# TIMEOUT_KSBUS_VBUSM_TO_GASKET_04301000h register map
Vendor: Texas Instruments
Peripheral module from a debugger description file (folder am62D).
Registers are 32-bit, read-only, reset 0x0 unless marked. A register's access mark holds for its fields unless they carry their own. Offsets are as the file gives them; lines under a group give offsets from that group; [hi:lo] are bit positions; {n}, {i} and the like mark numbered series; 'fields as' and 'values as' point back to an identical list; <NAME> marks a mode.

## ksbus_vbusm_to_gasket
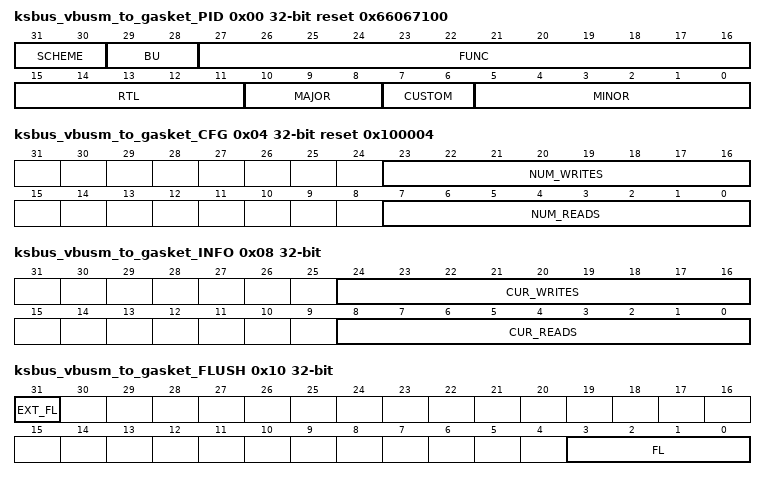
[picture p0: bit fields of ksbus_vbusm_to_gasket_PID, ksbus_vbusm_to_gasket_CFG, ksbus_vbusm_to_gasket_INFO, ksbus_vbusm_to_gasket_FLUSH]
0x00 ksbus_vbusm_to_gasket_PID reset 0x66067100 — The Revision Register contains the major and minor revisions for the module.
  [31:30] SCHEME — PID register scheme Reset Source: rst_mod_g_rst_n
  [29:28] BU — Business Unit: 10 = Processors Reset Source: rst_mod_g_rst_n
  [27:16] FUNC — Module ID Reset Source: rst_mod_g_rst_n
  [15:11] RTL — RTL revision. Will vary depending on release. Reset Source: rst_mod_g_rst_n
  [10:8] MAJOR — Major revision Reset Source: rst_mod_g_rst_n
  [7:6] CUSTOM — Custom Reset Source: rst_mod_g_rst_n
  [5:0] MINOR — Minor revision Reset Source: rst_mod_g_rst_n
0x04 ksbus_vbusm_to_gasket_CFG reset 0x100004 — The Configuration Register contains information about the configuration of the gasket.
  [23:16] NUM_WRITES — Total Number of slots in the write scoreboard Reset Source: rst_mod_g_rst_n
  [7:0] NUM_READS — Total Number of slots in the read scoreboard Reset Source: rst_mod_g_rst_n
0x08 ksbus_vbusm_to_gasket_INFO — The Info Register contains information about the current state of the gasket.
  [24:16] CUR_WRITES — Current number of occupied slots in the write scoreboard Reset Source: rst_mod_g_rst_n
  [8:0] CUR_READS — Current number of occupied slots in the read scoreboard Reset Source: rst_mod_g_rst_n
0x0C ksbus_vbusm_to_gasket_ENABLE rw — The Enable Register contains the gasket enable.
  [3:0] EN — Enable. 0 - Disabled, All other values - Enabled. Reset Source: rst_mod_g_rst_n
0x10 ksbus_vbusm_to_gasket_FLUSH access per field — The Flush Register contains software flush control.
  [31] EXT_FL ro — The value of external flush input Reset Source: rst_mod_g_rst_n
  [3:0] FL rw — SW control and indicator for whether the gasket is in flush mode. 4'b1111 - Flush mode, All other values - Normal mode. Reset Source: rst_mod_g_rst_n
0x14 ksbus_vbusm_to_gasket_TIMEOUT rw reset 0x3FFFFFFF — The Timeout Value Register contains the timeout value for scoreboarded transactions.
  [29:0] TO — The number of cycles in each eon. Each transaction can be outstanding for 2-3 eons before it times out. Reset Source: rst_mod_g_rst_n
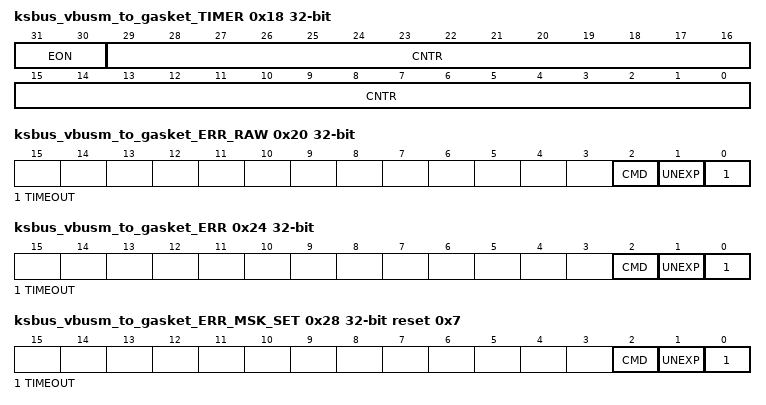
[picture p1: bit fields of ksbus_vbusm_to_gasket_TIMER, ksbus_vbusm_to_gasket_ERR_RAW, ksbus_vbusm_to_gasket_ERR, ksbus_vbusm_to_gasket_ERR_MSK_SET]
0x18 ksbus_vbusm_to_gasket_TIMER access not given — The Timer Register contains the current value for free-running timer.
  [31:30] EON ro — Current eon Reset Source: rst_mod_g_rst_n
  [29:0] CNTR — Current value of the free-running timer. It increments once per clock cycle when the gasket is enabled. Reset Source: rst_mod_g_rst_n (access R/WTC)
0x20 ksbus_vbusm_to_gasket_ERR_RAW access not given — This register contains the masked interrupt bits
  [2] CMD — Raw Command Error Interrupt Reset Source: rst_mod_g_rst_n (access R/W1TS)
  [1] UNEXP — Raw Unexpected Error Interrupt Reset Source: rst_mod_g_rst_n (access R/W1TS)
  [0] TIMEOUT — Raw Timeout Error Interrupt Reset Source: rst_mod_g_rst_n (access R/W1TS)
0x24 ksbus_vbusm_to_gasket_ERR access not given — This register contains the masked interrupt bits
  [2] CMD — Masked Command Error Interrupt Reset Source: rst_mod_g_rst_n (access R/W1TC)
  [1] UNEXP — Masked Unexpected Error Interrupt Reset Source: rst_mod_g_rst_n (access R/W1TC)
  [0] TIMEOUT — Masked Timeout Error Interrupt Reset Source: rst_mod_g_rst_n (access R/W1TC)
0x28 ksbus_vbusm_to_gasket_ERR_MSK_SET access not given reset 0x7 — This register contains interrupt mask set bits
  [2] CMD — Raw Command Error Interrupt Mask Set Reset Source: rst_mod_g_rst_n (access R/W1TS)
  [1] UNEXP — Raw Unexpected Error Interrupt Mask Set Reset Source: rst_mod_g_rst_n (access R/W1TS)
  [0] TIMEOUT — Raw Timeout Error Interrupt Mask Set Reset Source: rst_mod_g_rst_n (access R/W1TS)
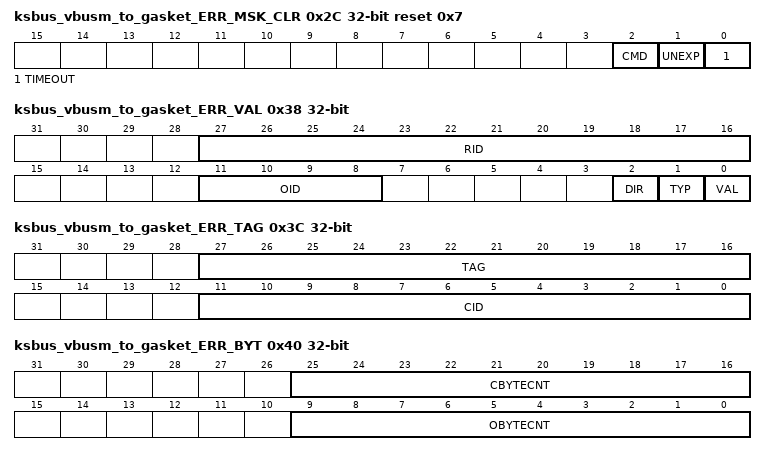
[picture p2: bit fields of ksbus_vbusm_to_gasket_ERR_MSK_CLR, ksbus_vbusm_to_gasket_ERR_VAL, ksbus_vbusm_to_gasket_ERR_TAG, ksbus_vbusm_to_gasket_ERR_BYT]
0x2C ksbus_vbusm_to_gasket_ERR_MSK_CLR access not given reset 0x7 — This register contains interrupt mask clear bits
  [2] CMD — Raw Command Error Interrupt Mask Clear Reset Source: rst_mod_g_rst_n (access R/W1TC)
  [1] UNEXP — Raw Unexpected Error Interrupt Mask Clear Reset Source: rst_mod_g_rst_n (access R/W1TC)
  [0] TIMEOUT — Raw Timeout Error Interrupt Mask Clear Reset Source: rst_mod_g_rst_n (access R/W1TC)
0x30 ksbus_vbusm_to_gasket_ERR_TM_INFO access not given — This register contains information about timeout interrupts
  [1:0] CNT — This field contains information about how many transactions have timed out since the last one was serviced. Writing to this register decrements the contents by the value written. The value saturates at 3. Reset Source: rst_mod_g_rst_n (access R/WTD)
0x34 ksbus_vbusm_to_gasket_ERR_UN_INFO access not given — This register contains information about unexpected interrupts
  [1:0] CNT — This field contains information about how many unexpected responses have been received since the last one was serviced. Writing to this register decrements the contents by the value written. The value saturates at 3. Reset Source: rst_mod_g_rst_n (access R/WTD)
0x38 ksbus_vbusm_to_gasket_ERR_VAL — This register contains information about transaction that caused the interrupt
  [27:16] RID — Route ID Indicator Reset Source: rst_mod_g_rst_n
  [11:8] OID — Order ID Indicator Reset Source: rst_mod_g_rst_n
  [2] DIR — Direction Indicator. 0-write. 1-read. Reset Source: rst_mod_g_rst_n
  [1] TYP — Error Type Indicator. 0-transaction timeout. 1-unexpected response. Reset Source: rst_mod_g_rst_n
  [0] VAL — Valid Indicator. If this field is a 1, then the contents of this and the below registers is considered valid: it contains the information about the transaction that was captured. If this field is 0 then this and the other listed registers are not valid. Reset Source: rst_mod_g_rst_n
0x3C ksbus_vbusm_to_gasket_ERR_TAG — This register contains information about transaction that caused the interrupt
  [27:16] TAG — Command Tag Indicator consisting of replacement CID for timeout error, or SID/RID for unexpected response error. Reset Source: rst_mod_g_rst_n
  [11:0] CID — Command ID Indicator. This is the original command id and is only valid on timeout error. Reset Source: rst_mod_g_rst_n
0x40 ksbus_vbusm_to_gasket_ERR_BYT — This register contains information about transaction that caused the interrupt
  [25:16] CBYTECNT — Current Bytecnt. For timeout error this is the number of bytes that were not returned. Reset Source: rst_mod_g_rst_n
  [9:0] OBYTECNT — Original Bytecnt. This field represents the transaction cbytecnt of the original command. Reset Source: rst_mod_g_rst_n
0x44 ksbus_vbusm_to_gasket_ERR_ADDR_U — This register contains information about transaction that caused the interrupt
  [31:0] ADDR — Upper bits of the address for the captured transaction. This is field is only valid for timeout error. Reset Source: rst_mod_g_rst_n
0x48 ksbus_vbusm_to_gasket_ERR_ADDR_L — This register contains information about transaction that caused the interrupt
  [31:0] ADDR — Lower bits of the address for the captured transaction. This is field is only valid for timeout error. If the address width is less than 32, then the bits above the address range will be read as 0. Reset Source: rst_mod_g_rst_n
